VERSION ""

NS_ :

BS_:

BU_: WaveSculptor22_Right EVDriverControls

BO_ 128 WS22Right_IDInfo: 8 WaveSculptor22_Right
 SG_ TritiumID : 0|32@1+ (1,0) [0|0] "" Vector__XXX
 SG_ SerialNumber : 32|32@1+ (1,0) [0|0] "" Vector__XXX

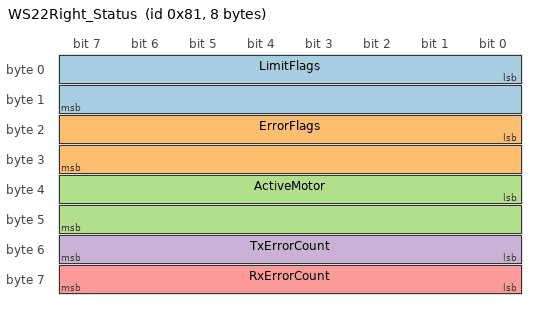
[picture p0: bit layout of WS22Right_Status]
BO_ 129 WS22Right_Status: 8 WaveSculptor22_Right
 SG_ LimitFlags : 0|16@1+ (1,0) [0|0] "" Vector__XXX
 SG_ ErrorFlags : 16|16@1+ (1,0) [0|0] "" Vector__XXX
 SG_ ActiveMotor : 32|16@1+ (1,0) [0|0] "" Vector__XXX
 SG_ TxErrorCount : 48|8@1+ (1,0) [0|0] "" Vector__XXX
 SG_ RxErrorCount : 56|8@1+ (1,0) [0|0] "" Vector__XXX

BO_ 130 WS22Right_BusMeasurement: 8 WaveSculptor22_Right
 SG_ BusVoltage : 0|32@1- (1,0) [0|0] "V" Vector__XXX
 SG_ BusCurrent : 32|32@1- (1,0) [0|0] "A" Vector__XXX

BO_ 131 WS22Right_VelocityMeasurement: 8 WaveSculptor22_Right
 SG_ MotorVelocity : 0|32@1- (1,0) [0|0] "rpm" Vector__XXX
 SG_ VehicleVelocity : 32|32@1- (1,0) [0|0] "m/s" Vector__XXX

BO_ 132 WS22Right_PhaseCurrentMeasurement: 8 WaveSculptor22_Right
 SG_ PhaseCurrentB : 0|32@1- (1,0) [0|0] "A_rms" Vector__XXX
 SG_ PhaseCurrentC : 32|32@1- (1,0) [0|0] "A_rms" Vector__XXX

BO_ 133 WS22Right_MotorVoltageVectorMeasurement: 8 WaveSculptor22_Right
 SG_ Vq : 0|32@1- (1,0) [0|0] "V" Vector__XXX
 SG_ Vd : 32|32@1- (1,0) [0|0] "V" Vector__XXX

BO_ 134 WS22Right_MotorCurrentVectorMeasurement: 8 WaveSculptor22_Right
 SG_ Iq : 0|32@1- (1,0) [0|0] "A" Vector__XXX
 SG_ Id : 32|32@1- (1,0) [0|0] "A" Vector__XXX

BO_ 135 WS22Right_MotorBackEMFMeasurementPrediction: 8 WaveSculptor22_Right
 SG_ BEMFq : 0|32@1- (1,0) [0|0] "V" Vector__XXX
 SG_ BEMFd : 32|32@1- (1,0) [0|0] "V" Vector__XXX

BO_ 136 WS22Right_VoltageRail15VMeasurement: 8 WaveSculptor22_Right
 SG_ Supply15V : 32|32@1- (1,0) [0|0] "V" Vector__XXX
 SG_ ReservedSupply15V : 0|32@1- (1,0) [0|0] "" Vector__XXX

BO_ 137 WS22Right_VoltageRail3V31V9Measurement: 8 WaveSculptor22_Right
 SG_ Supply1V9 : 0|32@1- (1,0) [0|0] "V" Vector__XXX
 SG_ Supply3V3 : 32|32@1- (1,0) [0|0] "V" Vector__XXX

BO_ 138 WS22Right_Reserved0A: 8 WaveSculptor22_Right
 SG_ Reserved0A0 : 0|32@1- (1,0) [0|0] "" Vector__XXX
 SG_ Reserved0A1 : 32|32@1- (1,0) [0|0] "" Vector__XXX

BO_ 139 WS22Right_HeatsinkMotorTempMeasurement: 8 WaveSculptor22_Right
 SG_ MotorTemp : 0|32@1- (1,0) [0|0] "C" Vector__XXX
 SG_ HeatsinkTemp : 32|32@1- (1,0) [0|0] "C" Vector__XXX

BO_ 140 WS22Right_DspBoardTempMeasurement: 8 WaveSculptor22_Right
 SG_ DspBoardTemp : 0|32@1- (1,0) [0|0] "C" Vector__XXX
 SG_ ReservedDspBoardTemp : 32|32@1- (1,0) [0|0] "" Vector__XXX

BO_ 141 WS22Right_Reserved0D: 8 WaveSculptor22_Right
 SG_ Reserved0D0 : 0|32@1- (1,0) [0|0] "" Vector__XXX
 SG_ Reserved0D1 : 32|32@1- (1,0) [0|0] "" Vector__XXX

BO_ 142 WS22Right_OdometerBusAhMeasurement: 8 WaveSculptor22_Right
 SG_ Odometer : 0|32@1- (1,0) [0|0] "m" Vector__XXX
 SG_ DCBusAh : 32|32@1- (1,0) [0|0] "Ah" Vector__XXX

BO_ 151 WS22Right_SlipSpeedMeasurement: 8 WaveSculptor22_Right
 SG_ SlipSpeed : 32|32@1- (1,0) [0|0] "Hz" Vector__XXX
 SG_ ReservedSlipSpeed : 0|32@1- (1,0) [0|0] "" Vector__XXX

BO_ 65 WS22Right_MotorDriveCommand: 8 EVDriverControls
 SG_ MotorVelocityCommand : 0|32@1- (1,0) [0|0] "rpm" Vector__XXX
 SG_ MotorCurrentCommand : 32|32@1- (1,0) [0|0] "%" Vector__XXX

BO_ 66 WS22Right_MotorPowerCommand: 8 EVDriverControls
 SG_ ReservedMotorPowerCommand : 0|32@1- (1,0) [0|0] "" Vector__XXX
 SG_ BusCurrentCommand : 32|32@1- (1,0) [0|0] "%" Vector__XXX

BO_ 67 WS22Right_ResetCommand: 8 EVDriverControls
 SG_ UnusedResetCommand0 : 0|32@1- (1,0) [0|0] "" Vector__XXX
 SG_ UnusedResetCommand1 : 32|32@1- (1,0) [0|0] "" Vector__XXX

BO_ 146 WS22Right_ActiveMotorChange: 8 EVDriverControls
 SG_ ActiveMotorCommand : 0|48@1+ (1,0) [0|0] "ASCII" Vector__XXX
 SG_ ConfigurationAccessKey : 48|16@1+ (1,0) [0|0] "" Vector__XXX

CM_ BO_ 128 "The periodic broadcast of this message cannot be disabled. It is needed to find the motor controller on the network if the base address is lost or mis-configured.";
CM_ SG_ 128 TritiumID "Device identifier. 0x00004003";
CM_ SG_ 128 SerialNumber "Device serial number, allocated at manufacture.";
CM_ SG_ 129 LimitFlags "Flags indicate which control loop is limiting the output current of the motor controller.";
CM_ SG_ 129 ErrorFlags "Flags indicate errors.";
CM_ SG_ 129 ActiveMotor "The index of the active motor currently being used.";
CM_ SG_ 129 TxErrorCount "The DSP CAN transmission error counter (CAN 2.0)";
CM_ SG_ 129 RxErrorCount "The DSP CAN receive error counter (CAN 2.0)";
CM_ SG_ 130 BusVoltage "DC bus voltage at the controller.";
CM_ SG_ 130 BusCurrent "Current drawn from the DC bus by the controller.";
CM_ SG_ 131 MotorVelocity "Motor angular frequency in revolutions per minute.";
CM_ SG_ 131 VehicleVelocity "Vehicle velocity in metres / second.";
CM_ BO_ 132 "While the motor is rotating at speed these two currents should be equal. At extremely low commutation speeds these two currents will only match in one third of the motor position, the other two thirds will involve current also flowing in Phase A.";
CM_ SG_ 132 PhaseCurrentB "RMS current in motor Phase B.";
CM_ SG_ 132 PhaseCurrentC "RMS current in motor Phase C.";
CM_ SG_ 133 Vq "Imaginary component of the applied non-rotating voltage vector to the motor.";
CM_ SG_ 133 Vd "Real component of the applied non-rotating voltage vector to the motor.";
CM_ SG_ 134 Iq "Imaginary component of the applied non-rotating current vector to the motor. This current produces torque in the motor and should be in phase with the back-EMF of the motor";
CM_ SG_ 134 Id "Real component of the applied non-rotating current vector to the motor. This vector represents the field current of the motor.";
CM_ SG_ 135 BEMFq "The peak of the phase to neutral motor voltage.";
CM_ SG_ 135 BEMFd "By definition this value is always 0V.";
CM_ SG_ 136 Supply15V "Actual voltage level of the 15V power rail.";
CM_ SG_ 137 Supply1V9 "Actual voltage level of the 1.9V DSP power rail.";
CM_ SG_ 137 Supply3V3 "Actual voltage level of the 3.3V power rail.";
CM_ SG_ 139 MotorTemp "Internal temperature of the motor";
CM_ SG_ 139 HeatsinkTemp "Internal temperature of Heat-sink (case).";
CM_ SG_ 140 DspBoardTemp "Temperature of the DSP board.";
CM_ SG_ 142 Odometer "Distance the vehicle has travelled since reset.";
CM_ SG_ 142 DCBusAh "Charge flow into the controller DC bus from the time of reset.";
CM_ SG_ 151 SlipSpeed "Slip speed when driving an induction motor.";
CM_ SG_ 65 MotorVelocityCommand "Desired motor velocity set point in rpm.";
CM_ SG_ 65 MotorCurrentCommand "Desired motor current set point as a percentage of maximum current setting.";
CM_ SG_ 66 BusCurrentCommand "Desired set point of current drawn from the bus by the controller as a percentage of absolute bus current limit.";
CM_ BO_ 67 "Send a command from this address to reset the software in the WaveSculptor.";
CM_ BO_ 146 "Send this command to change the active motor. Note that the controller will save the active motor to the EEPROM config memory, so what you send will survive a reset. This has a downside that you don't want to be sending it constantly, as you'll wear out the EEPROM. Example to set the active motor to motor slot 5: CAN ID = 0x412, Data = 0x00 05 54 4F 4D 54 43 41";
CM_ SG_ 146 ActiveMotorCommand "Must spell \"ACTMOT\" in ASCII (0x54 4F 4D 54 43 41).";
CM_ SG_ 146 ConfigurationAccessKey "Desired active motor (0 to 9).";
BA_DEF_ BO_  "GenMsgCycleTime" INT 2 50000;
BA_DEF_ BU_  "GenNodAutoGenSnd" ENUM  "No","Yes";
BA_DEF_ BU_  "GenNodAutoGenDsp" ENUM  "No","Yes";
BA_DEF_  "GenEnvVarEndingDsp" STRING ;
BA_DEF_  "GenEnvVarEndingSnd" STRING ;
BA_DEF_  "GenEnvVarPrefix" STRING ;
BA_DEF_DEF_  "GenMsgCycleTime" 100;
BA_DEF_DEF_  "GenNodAutoGenSnd" "Yes";
BA_DEF_DEF_  "GenNodAutoGenDsp" "Yes";
BA_DEF_DEF_  "GenEnvVarEndingDsp" "Dsp";
BA_DEF_DEF_  "GenEnvVarEndingSnd" "Snd";
BA_DEF_DEF_  "GenEnvVarPrefix" "Env";
BA_ "GenMsgCycleTime" BO_ 128 1000;
BA_ "GenMsgCycleTime" BO_ 129 200;
BA_ "GenMsgCycleTime" BO_ 130 200;
BA_ "GenMsgCycleTime" BO_ 131 200;
BA_ "GenMsgCycleTime" BO_ 132 200;
BA_ "GenMsgCycleTime" BO_ 133 200;
BA_ "GenMsgCycleTime" BO_ 134 200;
BA_ "GenMsgCycleTime" BO_ 135 200;
BA_ "GenMsgCycleTime" BO_ 136 1000;
BA_ "GenMsgCycleTime" BO_ 137 1000;
BA_ "GenMsgCycleTime" BO_ 138 0;
BA_ "GenMsgCycleTime" BO_ 139 1000;
BA_ "GenMsgCycleTime" BO_ 140 1000;
BA_ "GenMsgCycleTime" BO_ 141 1000;
BA_ "GenMsgCycleTime" BO_ 142 1000;
BA_ "GenMsgCycleTime" BO_ 151 200;
BA_ "GenMsgCycleTime" BO_ 65 250;
SIG_VALTYPE_ 130 BusVoltage : 1;
SIG_VALTYPE_ 130 BusCurrent : 1;
SIG_VALTYPE_ 131 MotorVelocity : 1;
SIG_VALTYPE_ 131 VehicleVelocity : 1;
SIG_VALTYPE_ 132 PhaseCurrentB : 1;
SIG_VALTYPE_ 132 PhaseCurrentC : 1;
SIG_VALTYPE_ 133 Vq : 1;
SIG_VALTYPE_ 133 Vd : 1;
SIG_VALTYPE_ 134 Iq : 1;
SIG_VALTYPE_ 134 Id : 1;
SIG_VALTYPE_ 135 BEMFq : 1;
SIG_VALTYPE_ 135 BEMFd : 1;
SIG_VALTYPE_ 136 Supply15V : 1;
SIG_VALTYPE_ 136 ReservedSupply15V : 1;
SIG_VALTYPE_ 137 Supply1V9 : 1;
SIG_VALTYPE_ 137 Supply3V3 : 1;
SIG_VALTYPE_ 138 Reserved0A0 : 1;
SIG_VALTYPE_ 138 Reserved0A1 : 1;
SIG_VALTYPE_ 139 MotorTemp : 1;
SIG_VALTYPE_ 139 HeatsinkTemp : 1;
SIG_VALTYPE_ 140 DspBoardTemp : 1;
SIG_VALTYPE_ 140 ReservedDspBoardTemp : 1;
SIG_VALTYPE_ 141 Reserved0D0 : 1;
SIG_VALTYPE_ 141 Reserved0D1 : 1;
SIG_VALTYPE_ 142 Odometer : 1;
SIG_VALTYPE_ 142 DCBusAh : 1;
SIG_VALTYPE_ 151 SlipSpeed : 1;
SIG_VALTYPE_ 151 ReservedSlipSpeed : 1;
SIG_VALTYPE_ 65 MotorVelocityCommand : 1;
SIG_VALTYPE_ 65 MotorCurrentCommand : 1;
SIG_VALTYPE_ 66 ReservedMotorPowerCommand : 1;
SIG_VALTYPE_ 66 BusCurrentCommand : 1;
SIG_VALTYPE_ 67 UnusedResetCommand0 : 1;
SIG_VALTYPE_ 67 UnusedResetCommand1 : 1;
